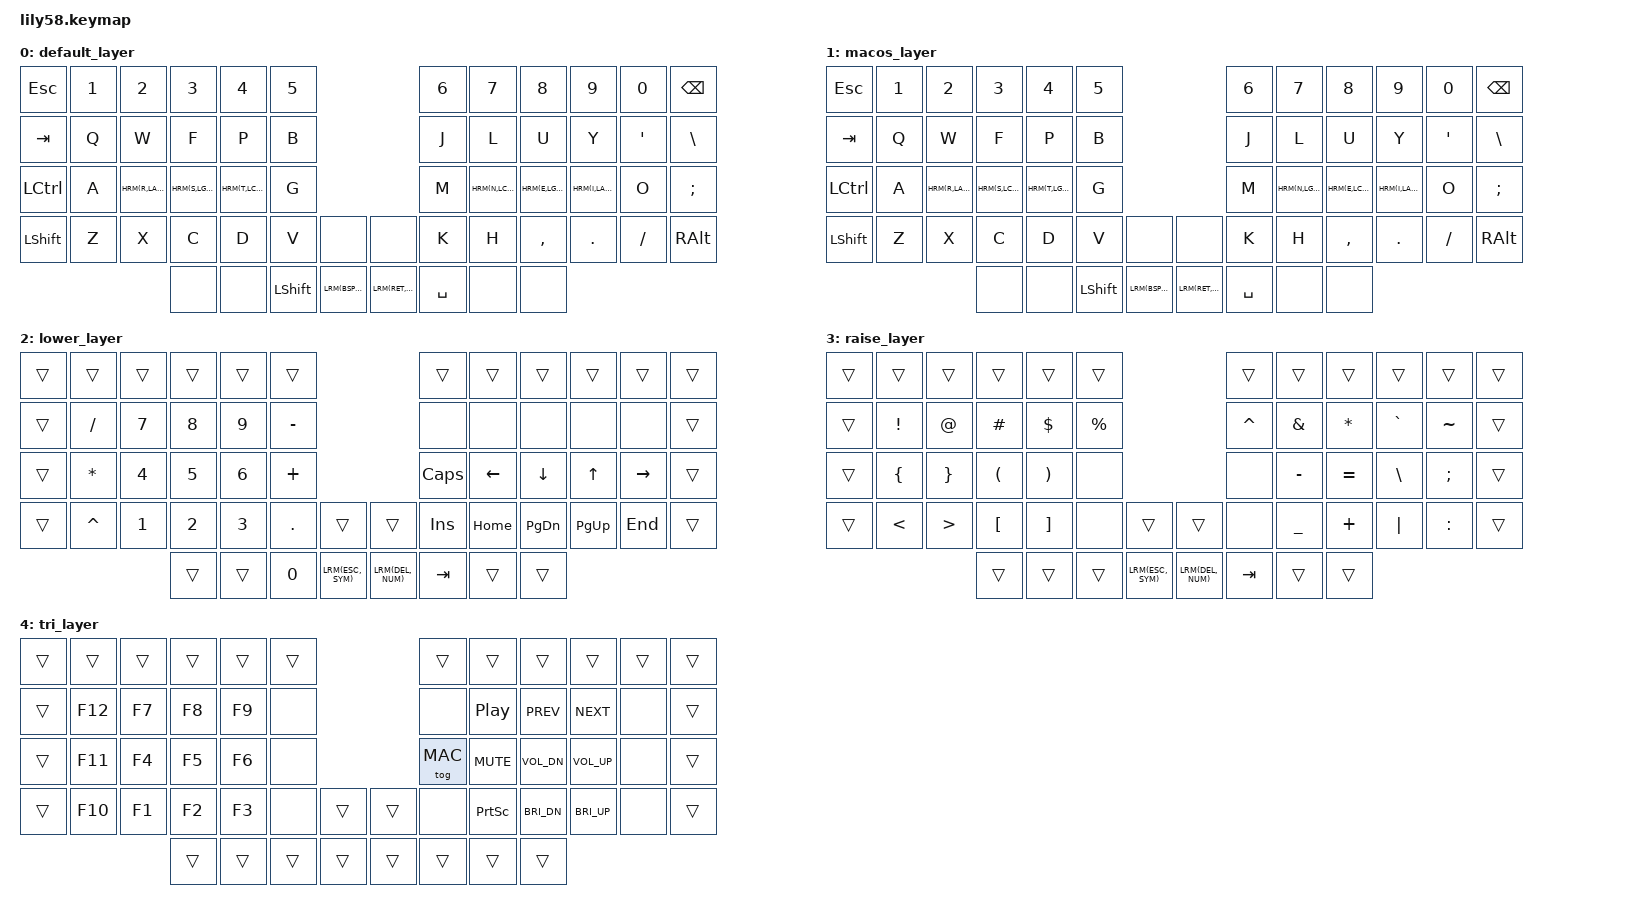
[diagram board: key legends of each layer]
/*
 * Copyright (c) 2020 The ZMK Contributors
 *
 * SPDX-License-Identifier: MIT
 */

#include <behaviors.dtsi>
#include <dt-bindings/zmk/keys.h>
#include <dt-bindings/zmk/bt.h>
#include <dt-bindings/zmk/ext_power.h>

#define WIN   0
#define MAC   1
#define LOWER 2
#define RAISE 3

#define NUM 2
#define SYM 3
#define TRI 4

#define HRM(key,mod)   &hrm mod   key
#define LRM(key,layer) &lrm layer key

&lt {
    flavor = "balanced";
    tapping-term-ms = <280>;
    quick-tap-ms = <175>;
    require-prior-idle-ms = <150>;
};

/ {
    conditional_layers {
        compatible = "zmk,conditional-layers";
        tri_layer {
            if-layers = <NUM SYM>;
            then-layer = <TRI>;
        };
    };

    behaviors {
        hrm: home_row_mod {
            compatible = "zmk,behavior-hold-tap";
            #binding-cells = <2>;
            flavor = "balanced";
            tapping-term-ms = <280>;
            quick-tap-ms = <175>;
            require-prior-idle-ms = <150>;
            bindings = <&kp>, <&kp>;
        };

        lrm: layer_mod {
            compatible = "zmk,behavior-hold-tap";
            #binding-cells = <2>;
            flavor = "balanced";
            tapping-term-ms = <280>;
            quick-tap-ms = <175>;
            require-prior-idle-ms = <150>;
            bindings = <&mo>, <&kp>;
        };
        
        /* // hybrid keys
        bsdel: backspace_delete {
            compatible = "zmk,behavior-mod-morph";
            #binding-cells = <0>;
            bindings = <&kp BSPC>, <&kp DEL>;
            mods = <(MOD_LALT|MOD_RALT)>;
        };
        rtesc: return_escape {
            compatible = "zmk,behavior-mod-morph";
            #binding-cells = <0>;
            bindings = <&kp RET>, <&kp ESC>;
            mods = <(MOD_LALT|MOD_RALT)>;
        };
        sptab: space_tab {
            compatible = "zmk,behavior-mod-morph";
            #binding-cells = <0>;
            bindings = <&kp SPACE>, <&kp TAB>;
            mods = <(MOD_LALT|MOD_RALT)>;
        };
        
        // hybrid layer keys
        lbd: layer_backspace_delete {
            compatible = "zmk,behavior-hold-tap";
            #binding-cells = <2>;
            flavor = "balanced";
            tapping-term-ms = <280>;
            quick-tap-ms = <175>;
            require-prior-idle-ms = <150>;
            bindings = <&mo>, <&bsdel>;
        };
        lre: layer_return_escape {
            compatible = "zmk,behavior-hold-tap";
            #binding-cells = <2>;
            flavor = "balanced";
            tapping-term-ms = <280>;
            quick-tap-ms = <175>;
            require-prior-idle-ms = <150>;
            bindings = <&mo>, <&rtesc>;
        }; */
    };

    keymap {
        compatible = "zmk,keymap";

        default_layer {
            bindings = <
                // ,----------,------,-----------,-----------,------------,---------,                              ,---------,------------,-----------,-----------,--------,--------,
                // | ESC      | 1    | 2         | 3         | 4          | 5       |                              | 6       | 7          | 8         | 9         | 0      | BS     |
                    &kp ESC    &kp N1 &kp N2      &kp N3      &kp N4       &kp N5                                   &kp N6    &kp N7       &kp N8      &kp N9      &kp N0   &kp BSPC
                // |----------+------+-----------+-----------+------------+---------|                              |---------+------------+-----------+-----------+--------+--------|
                // | TAB      | Q    | W         | F         | P          | B       |                              | J       | L          | U         | Y         | SQT    | BSLH   |
                    &kp TAB    &kp Q  &kp W       &kp F       &kp P        &kp B                                    &kp J     &kp L        &kp U       &kp Y       &kp SQT  &kp BSLH
                // |----------+------+-----------+-----------+------------+---------|                              |---------+------------+-----------+-----------+--------+--------|
                // | LCTRL    | A    | R / LALT  | S / LGUI  | T / LCTRL  | G       |                              | M       | N / LCTRL  | E / LGUI  | I / LALT  | O      | SEMI   |
                    &kp LCTRL  &kp A  HRM(R,LALT) HRM(S,LGUI) HRM(T,LCTRL) &kp G                                    &kp M     HRM(N,LCTRL) HRM(E,LGUI) HRM(I,LALT) &kp O    &kp SEMI
                // |----------+------+-----------+-----------+------------+---------+-------------,   ,------------+---------+------------+-----------+-----------+--------+--------|
                // | LSHFT    | Z    | X         | C         | D          | V       | --          |   | --         | K       | H          | COMMA     | DOT       | FSLH   | RALT   |
                    &kp LSHFT  &kp Z  &kp X       &kp C       &kp D        &kp V     &none             &none        &kp K     &kp H        &kp COMMA   &kp DOT     &kp FSLH &kp RALT
                // '----------'------'-----------+-----------+------------+---------+-------------|   |------------+---------+------------+-----------+-----------'--------'--------'
                //                               | --        | --         | LSHFT   | tBSPC hSYM  |   | tRET hNUM  | SPACE   | --         | --        | 
                                                  &none        &none       &kp LSHFT LRM(BSPC,SYM)     LRM(RET,NUM) &kp SPACE &none        &none
                //                               '-----------'------------'---------'-------------'   '------------'---------'------------'-----------'
            >;

            sensor-bindings = <&inc_dec_kp C_VOL_UP C_VOL_DN>;
        };

        macos_layer {
            bindings = <
                // ,----------,------,-----------,------------,-----------,---------,                              ,---------,-----------,------------,-----------,--------,--------,
                // | ESC      | 1    | 2         | 3          | 4         | 5       |                              | 6       | 7         | 8          | 9         | 0      | BS     |
                    &kp ESC    &kp N1 &kp N2      &kp N3       &kp N4      &kp N5                                   &kp N6    &kp N7      &kp N8       &kp N9      &kp N0   &kp BSPC
                // |----------+------+-----------+------------+-----------+---------|                              |---------+-----------+------------+-----------+--------+--------|
                // | TAB      | Q    | W         | F          | P         | B       |                              | J       | L         | U          | Y         | SQT    | BSLH   |
                    &kp TAB    &kp Q  &kp W       &kp F        &kp P       &kp B                                    &kp J     &kp L       &kp U        &kp Y       &kp SQT  &kp BSLH
                // |----------+------+-----------+------------+-----------+---------|                              |---------+-----------+------------+-----------+--------+--------|
                // | LCTRL    | A    | R / LALT  | S / LCTRL  | T / LGUI  | G       |                              | M       | N / LGUI  | E / LCTRL  | I / LALT  | O      | SEMI   |
                    &kp LCTRL  &kp A  HRM(R,LALT) HRM(S,LCTRL) HRM(T,LGUI) &kp G                                    &kp M     HRM(N,LGUI) HRM(E,LCTRL) HRM(I,LALT) &kp O    &kp SEMI
                // |----------+------+-----------+------------+-----------+---------+-------------,   ,------------+---------+-----------+------------+-----------+--------+--------|
                // | LSHFT    | Z    | X         | C          | D         | V       | --          |   | --         | K       | H         | COMMA      | DOT       | FSLH   | RALT   |
                    &kp LSHFT  &kp Z  &kp X       &kp C        &kp D       &kp V     &none             &none        &kp K     &kp H       &kp COMMA    &kp DOT     &kp FSLH &kp RALT
                // '----------'------'-----------+------------+-----------+---------+-------------|   |------------+---------+-----------+------------+-----------'--------'--------'
                //                               | --         | --        | LSHFT   | tBSPC hSYM  |   | tRET hNUM  | SPACE   | --        | --         | 
                                                  &none        &none       &kp LSHFT LRM(BSPC,SYM)     LRM(RET,NUM) &kp SPACE &none       &none
                //                               '------------'-----------'---------'-------------'   '------------'---------'-----------'------------'
            >;

            sensor-bindings = <&inc_dec_kp C_VOL_UP C_VOL_DN>;
        };

        lower_layer {
            bindings = <
                // ,------,---------,------,------,------,---------,                               ,--------,--------,---------,---------,---------,------,
                // |      |         |      |      |      |         |                               |        |        |         |         |         |      |
                    &trans &trans    &trans &trans &trans &trans                                    &trans   &trans   &trans    &trans    &trans    &trans
                // |------+---------+------+------+------+---------|                               |--------+--------+---------+---------+---------+------|
                // |      | /       | 7    | 8    | 9    | -       |                               | --     | --     | --      | --      | --      |      |
                    &trans &kp FSLH  &kp N7 &kp N8 &kp N9 &kp MINUS                                 &none    &none    &none     &none     &none     &trans
                // |------+---------+------+------+------+---------|                               |--------+--------+---------+---------+---------+------|
                // |      | *       | 4    | 5    | 6    | +       |                               | CAPS   | LEFT   | DOWN    | UP      | RIGHT   |      |
                    &trans &kp STAR  &kp N4 &kp N5 &kp N6 &kp PLUS                                  &kp CAPS &kp LEFT &kp DOWN  &kp UP    &kp RIGHT &trans
                // |------+---------+------+------+------+---------+-------------,   ,-------------+--------+--------+---------+---------+---------+------|
                // |      | ^       | 1    | 2    | 3    | .       |             |   |             | INSERT | HOME   | PGDN    | PGUP    | END     |      |
                    &trans &kp CARET &kp N1 &kp N2 &kp N3 &kp DOT   &trans            &trans        &kp INS  &kp HOME &kp PG_DN &kp PG_UP &kp END   &trans
                // '------'---------'------+------+------+---------+-------------|   |-------------+--------+--------+---------+---------'---------'------'
                //                         |      |      | 0       |  tESC hTRI  |   |  tDEL hTRI  | TAB    |         |         | 
                                            &trans &trans &kp N0    LRM(ESC, SYM)     LRM(DEL, NUM) &kp TAB  &trans   &trans  
                //                         '------'------'---------'-------------'   '-------------'--------'---------'---------'
            >;

            sensor-bindings = <&inc_dec_kp C_VOL_UP C_VOL_DN>;
        };

        raise_layer {
            bindings = <
                // ,------,--------,--------,--------,--------,---------,                               ,---------,---------,---------,---------,---------,------,
                // |      |        |        |        |        |         |                               |         |         |         |         |         |      |
                    &trans &trans   &trans   &trans   &trans   &trans                                    &trans    &trans    &trans    &trans    &trans    &trans
                // |------+--------+--------+--------+--------+---------|                               |---------+---------+---------+---------+---------+------|
                // |      | !      | @      | #      | $      | %       |                               | ^       | &       | *       | `       | ~       |      |
                    &trans &kp EXCL &kp AT   &kp HASH &kp DLLR &kp PRCNT                                 &kp CARET &kp AMPS  &kp STAR  &kp GRAVE &kp TILDE &trans
                // |------+--------+--------+--------+--------+---------|                               |---------+---------+---------+---------+---------+------|
                // |      | {      | }      | (      | )      | --      |                               | --      | -       | =       | \       | ;       |      |
                    &trans &kp LBRC &kp RBRC &kp LPAR &kp RPAR &none                                     &none     &kp MINUS &kp EQUAL &kp BSLH  &kp SEMI  &trans
                // |------+--------+--------+--------+--------+---------+-------------,   ,-------------+---------+---------+---------+---------+---------+------|
                // |      | <      | >      | [      | ]      | --      |             |   |             | --      | _       | +       | |       | :       |      |
                    &trans &kp LT   &kp GT   &kp LBKT &kp RBKT &none     &trans            &trans        &none     &kp UNDER &kp PLUS  &kp PIPE  &kp COLON &trans
                // '------'--------'--------+--------+--------+---------+-------------|   |-------------+---------+---------+---------+---------'---------'------'
                //                          |        |        |         |  tESC hTRI  |   |  tDEL hTRI  | TAB     |         |         | 
                                             &trans   &trans   &trans    LRM(ESC, SYM)     LRM(DEL, NUM) &kp TAB   &trans   &trans  
                //                          '--------'--------'---------'-------------'   '-------------'---------'---------'---------'
            >;

            sensor-bindings = <&inc_dec_kp C_VOL_UP C_VOL_DN>;
        };

        tri_layer {
            bindings = <
                // ,------,--------,------,------,------,------,                 ,--------,----------,------------,------------,------,------,
                // |      |        |      |      |      |      |                 |        |          |            |            |      |      |
                    &trans &trans   &trans &trans &trans &trans                   &trans   &trans     &trans       &trans       &trans &trans
                // |------+--------+------+------+------+------|                 |--------+----------+------------+------------+------+------|
                // |      | F12    | F7   | F8   | F9   | --   |                 | --     | C_PP     | C_PREV     | C_NEXT     | --   |      |
                    &trans &kp F12  &kp F7 &kp F8 &kp F9 &none                    &none    &kp C_PP   &kp C_PREV   &kp C_NEXT   &none  &trans
                // |------+--------+------+------+------+------|                 |--------+----------+------------+------------+------+------|
                // |      | F11    | F4   | F5   | F6   | --   |                 | MAC LR | C_MUTE   | C_VOL_DN   | C_VOL_UP   | --   |      |
                    &trans &kp F11  &kp F4 &kp F5 &kp F6 &none                    &tog MAC &kp C_MUTE &kp C_VOL_DN &kp C_VOL_UP &none  &trans
                // |------+--------+------+------+------+------+------,   ,------+--------+----------+------------+------------+------+------|
                // |      | F10    | F1   | F2   | F3   | --   |      |   |      | --     | PRINT    | C_BRI_DN   | C_BRI_UP   | --   |      |
                    &trans &kp F10  &kp F1 &kp F2 &kp F3 &none  &trans     &trans &none    &kp PSCRN  &kp C_BRI_DN &kp C_BRI_UP &none  &trans
                // '------'--------'------+------+------+------+------|   |------+--------+----------+------------+------------'------'------'
                //                        |      |      |      |      |   |      |        |          |            | 
                                           &trans &trans &trans &trans     &trans &trans   &trans     &trans 
                //                        '------'------'------'------'   '------'--------'----------'------------'
            >;

            sensor-bindings = <&inc_dec_kp C_VOL_UP C_VOL_DN>;
        };
    };
};
